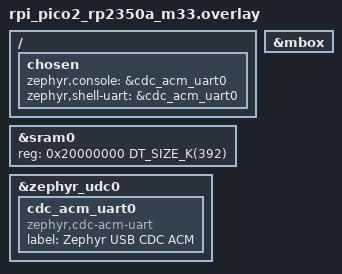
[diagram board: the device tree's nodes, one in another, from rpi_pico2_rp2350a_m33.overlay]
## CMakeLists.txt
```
# SPDX-License-Identifier: Apache-2.0

cmake_minimum_required(VERSION 3.20.0)

find_package(Zephyr REQUIRED HINTS $ENV{ZEPHYR_BASE})
project(rp2350_zephyr_multicore)

target_sources(app PRIVATE
    src/main.c
    src/core1_launch.c
    src/blink_shell.c
    src/core1_blob.c
)

include(cmake/core1.cmake)
```

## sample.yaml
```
sample:
  description: Bare-metal core1 LED blink demo with USB CDC-ACM console
  name: rp2350 zephyr multicore
common:
  min_ram: 16
  min_flash: 32
  tags: multicore
  platform_allow:
    - rpi_pico2/rp2350a/m33
tests:
  sample.multicore.blink:
    tags: multicore
```

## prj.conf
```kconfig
CONFIG_USB_DEVICE_STACK_NEXT=y
CONFIG_CDC_ACM_SERIAL_INITIALIZE_AT_BOOT=y

# Core0 <-> core1 SIO-FIFO mailbox (see &mbox in the board overlay).
CONFIG_MBOX=y

CONFIG_SERIAL=y
CONFIG_CONSOLE=y
CONFIG_SHELL=y
CONFIG_UART_CONSOLE=y
CONFIG_UART_LINE_CTRL=y

CONFIG_TEST_RANDOM_GENERATOR=y

CONFIG_INIT_STACKS=y

CONFIG_LOG=y
CONFIG_LOG_DEFAULT_LEVEL=2
```

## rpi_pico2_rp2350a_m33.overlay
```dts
/* Reserve the top 128KB (2x64KB) of SRAM for the bare-metal core1 image at
 * 0x20062000-0x20082000; Zephyr/core0 is confined to the bottom 392KB.
 * CONFIG_SRAM_SIZE/CONFIG_SRAM_BASE_ADDRESS (and thus the linker RAM region
 * and the RP2350 MPU SRAM_0 region) derive directly from this node's reg. */
&sram0 {
    reg = <0x20000000 DT_SIZE_K(392)>;
};

&mbox {
    status = "okay";
};

/ {
    chosen {
        zephyr,console = &cdc_acm_uart0;
        zephyr,shell-uart = &cdc_acm_uart0;
    };
};

&zephyr_udc0 {
    cdc_acm_uart0: cdc_acm_uart0 {
        status = "okay";
        compatible = "zephyr,cdc-acm-uart";
        label = "Zephyr USB CDC ACM";
    };
};
```

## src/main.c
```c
#include <zephyr/kernel.h>
#include <zephyr/logging/log.h>
LOG_MODULE_REGISTER(multicore_demo, LOG_LEVEL_INF);

#include "core1_launch.h"
#include "blink_shell.h"

int main(void)
{
	LOG_INF("Core0 up; launching core1");

	if (core1_launch()) {
		LOG_ERR("Failed to launch core1");
	}

	if (blink_mbox_init()) {
		LOG_ERR("Failed to init core1 mailbox");
	}

	while (1) {
		k_sleep(K_MSEC(1000));
	}

	return 0;
}
```

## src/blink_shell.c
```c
#include <stdlib.h>
#include <errno.h>

#include <zephyr/kernel.h>
#include <zephyr/device.h>
#include <zephyr/devicetree.h>
#include <zephyr/drivers/mbox.h>
#include <zephyr/shell/shell.h>

#include "../core1/mailbox_proto.h"
#include "blink_shell.h"

static const struct device *mbox_dev;
static struct k_sem reply_sem;
static volatile uint32_t last_reply;

static void mbox_cb(const struct device *dev, mbox_channel_id_t channel_id,
		     void *user_data, struct mbox_msg *msg)
{
	ARG_UNUSED(dev);
	ARG_UNUSED(channel_id);
	ARG_UNUSED(user_data);

	last_reply = *(const uint32_t *)msg->data;
	k_sem_give(&reply_sem);
}

int blink_mbox_init(void)
{
	mbox_dev = DEVICE_DT_GET(DT_NODELABEL(mbox));
	if (!device_is_ready(mbox_dev)) {
		return -ENODEV;
	}

	k_sem_init(&reply_sem, 0, 1);

	int ret = mbox_register_callback(mbox_dev, 0, mbox_cb, NULL);

	if (ret) {
		return ret;
	}

	return mbox_set_enabled(mbox_dev, 0, true);
}

static int blink_roundtrip(uint32_t word, uint32_t *reply_out)
{
	struct mbox_msg msg = {
		.data = &word,
		.size = sizeof(word),
	};

	int ret = mbox_send(mbox_dev, 0, &msg);

	if (ret) {
		return ret;
	}

	if (k_sem_take(&reply_sem, K_MSEC(1000)) != 0) {
		return -ETIMEDOUT;
	}

	*reply_out = last_reply;
	return 0;
}

static int cmd_blink_rate_get(const struct shell *sh, size_t argc, char **argv)
{
	ARG_UNUSED(argc);
	ARG_UNUSED(argv);

	uint32_t reply;

	if (blink_roundtrip(MBOX_MSG_MAKE_GET(), &reply)) {
		shell_error(sh, "core1 did not respond");
		return -1;
	}

	shell_print(sh, "blink rate: %u ms", MBOX_MSG_RATE(reply));
	return 0;
}

static int cmd_blink_rate_set(const struct shell *sh, size_t argc, char **argv)
{
	ARG_UNUSED(argc);

	uint32_t ms = strtoul(argv[1], NULL, 10);
	uint32_t reply;

	if (blink_roundtrip(MBOX_MSG_MAKE_SET(ms), &reply)) {
		shell_error(sh, "core1 did not respond");
		return -1;
	}

	shell_print(sh, "blink rate set to: %u ms", MBOX_MSG_RATE(reply));
	return 0;
}

SHELL_STATIC_SUBCMD_SET_CREATE(sub_blink_rate,
	SHELL_CMD_ARG(get, NULL, "Get the core1 LED blink rate (ms)", cmd_blink_rate_get, 1, 0),
	SHELL_CMD_ARG(set, NULL, "Set the core1 LED blink rate (ms)", cmd_blink_rate_set, 2, 0),
	SHELL_SUBCMD_SET_END
);

SHELL_STATIC_SUBCMD_SET_CREATE(sub_blink,
	SHELL_CMD(rate, &sub_blink_rate, "Blink rate control", NULL),
	SHELL_SUBCMD_SET_END
);

SHELL_CMD_REGISTER(blink, &sub_blink, "Core1 LED blink control", NULL);
```

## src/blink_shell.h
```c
#ifndef BLINK_SHELL_H
#define BLINK_SHELL_H

/* Sets up the mbox device and callback used by the `blink rate` shell
 * commands to talk to core1. Returns 0 on success.
 */
int blink_mbox_init(void);

#endif /* BLINK_SHELL_H */
```
